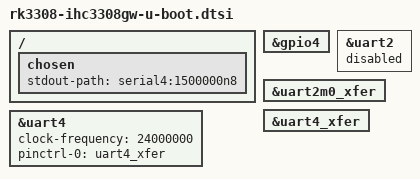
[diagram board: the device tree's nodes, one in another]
// SPDX-License-Identifier: GPL-2.0+
/* Reuse the reference board's GMAC, regulator and common SPL properties. */
#include "rk3308-roc-cc-u-boot.dtsi"

/ {
	chosen {
		stdout-path = "serial4:1500000n8";
	};
};

&gpio4 {
	bootph-all;
};

&uart2 {
	/delete-property/ bootph-all;
	status = "disabled";
};

&uart2m0_xfer {
	/delete-property/ bootph-all;
};

&uart4 {
	bootph-all;
	clock-frequency = <24000000>;
	pinctrl-0 = <&uart4_xfer>;
	status = "okay";
	/delete-property/ uart-has-rtscts;
};

&uart4_xfer {
	bootph-all;
};
